# CH32V20xxx register map
Vendor: WCH Ltd.; File version: 1.0
Registers are 32-bit, read-write, reset 0x0 unless marked. A register's access mark holds for its fields unless they carry their own. Offsets are from the block's base; [hi:lo] are bit positions; {n}, {i} and the like mark numbered series.

## EXTI
Base 0x40010400
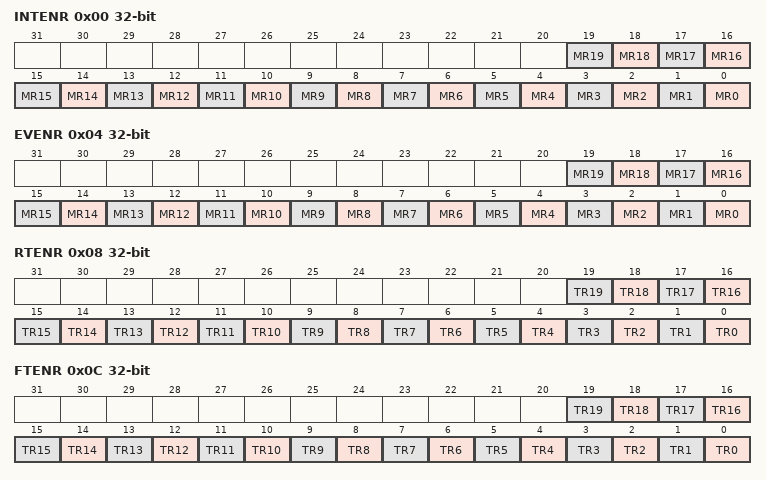
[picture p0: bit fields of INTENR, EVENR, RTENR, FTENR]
0x00 INTENR — Interrupt mask register (EXTI_INTENR)
  [n] MR{n} (n=0..19) — Interrupt Mask on line {n}
0x04 EVENR — Event mask register (EXTI_EVENR)
  [n] MR{n} (n=0..19) — Event Mask on line {n}
0x08 RTENR — Rising Trigger selection register (EXTI_RTENR)
  [n] TR{n} (n=0..19) — Rising trigger event configuration of line {n}
0x0C FTENR — Falling Trigger selection register (EXTI_FTENR)
  [n] TR{n} (n=0..19) — Falling trigger event configuration of line {n}
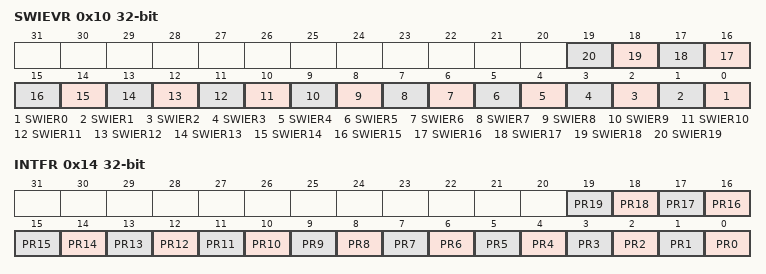
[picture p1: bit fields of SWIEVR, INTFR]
0x10 SWIEVR — Software interrupt event register (EXTI_SWIEVR)
  [n] SWIER{n} (n=0..19) — Software Interrupt on line {n}
0x14 INTFR — Pending register (EXTI_INTFR)
  [n] PR{n} (n=0..19) — Pending bit {n}

## RTC — Real time clock
Base 0x40002800
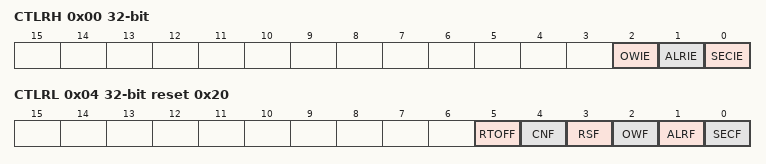
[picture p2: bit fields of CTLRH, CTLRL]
0x00 CTLRH — RTC Control Register High
  [2] OWIE — Overflow interrupt Enable
  [1] ALRIE — Alarm interrupt Enable
  [0] SECIE — Second interrupt Enable
0x04 CTLRL access per field reset 0x20 — RTC Control Register Low
  [5] RTOFF ro — RTC operation OFF
  [4] CNF rw — Configuration Flag
  [3] RSF rw — Registers Synchronized Flag
  [2] OWF rw — Overflow Flag
  [1] ALRF rw — Alarm Flag
  [0] SECF rw — Second Flag
0x08 PSCRH wo — RTC Prescaler Load Register High
  [3:0] PRLH
0x0C PSCRL wo reset 0x8000 — RTC Prescaler Load Register Low
  [15:0] PRLL — RTC Prescaler Divider Register Low
0x10 DIVH ro — RTC Prescaler Divider Register High
  [3:0] DIVH — RTC prescaler divider register high
0x14 DIVL ro reset 0x8000 — RTC Prescaler Divider Register Low
  [15:0] DIVL — RTC prescaler divider register Low
0x18 CNTH — RTC Counter Register High
  [15:0] CNTH — RTC counter register high
0x1C CNTL — RTC Counter Register Low
  [15:0] CNTL — RTC counter register Low
0x20 ALRMH wo reset 0xFFFF — RTC Alarm Register High
  [15:0] ALRH — RTC alarm register high
0x24 ALRML wo reset 0xFFFF — RTC Alarm Register Low
  [15:0] ALRL — RTC alarm register low

## BKP — Backup registers
Base 0x40006C00
{0x0+4i} DATAR{i} (i=1..10) — Backup data register (BKP_DR)
  [15:0] D{i} — Backup data
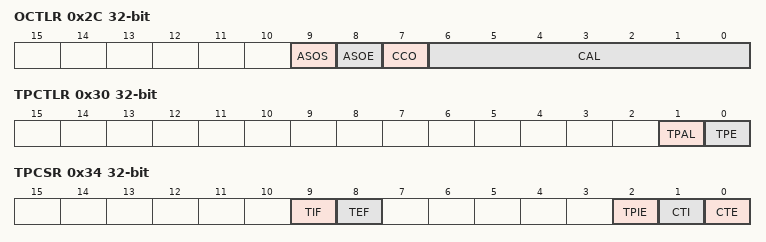
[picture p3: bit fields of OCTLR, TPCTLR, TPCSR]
0x2C OCTLR — RTC clock calibration register (BKP_OCTLR)
  [9] ASOS — Alarm or second output selection
  [8] ASOE — Alarm or second output enable
  [7] CCO — Calibration Clock Output
  [6:0] CAL — Calibration value
0x30 TPCTLR — Backup control register (BKP_TPCTLR)
  [1] TPAL — Tamper pin active level
  [0] TPE — Tamper pin enable
0x34 TPCSR access per field — BKP_TPCSR control/status register (BKP_CSR)
  [9] TIF ro — Tamper Interrupt Flag
  [8] TEF ro — Tamper Event Flag
  [2] TPIE rw — Tamper Pin interrupt enable
  [1] CTI wo — Clear Tamper Interrupt
  [0] CTE wo — Clear Tamper event
{0x14+4i} DATAR{i} (i=11..13) — Backup data register (BKP_DR)
  [15:0] DR{i} — Backup data
{0x14+4i} DATAR{i} (i=14..42) — Backup data register (BKP_DR)
  [15:0] D{i} — Backup data

## IWDG — Independent watchdog
Base 0x40003000
0x00 CTLR wo — Key register (IWDG_CTLR)
  [15:0] KEY — Key value
0x04 PSCR — Prescaler register (IWDG_PSCR)
  [2:0] PR — Prescaler divider
0x08 RLDR reset 0xFFF — Reload register (IWDG_RLDR)
  [11:0] RL — Watchdog counter reload value
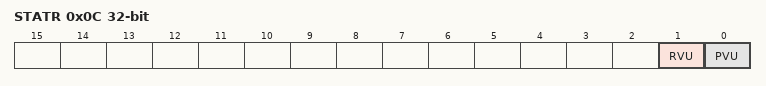
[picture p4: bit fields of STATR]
0x0C STATR ro — Status register (IWDG_SR)
  [1] RVU — Watchdog counter reload value update
  [0] PVU — Watchdog prescaler value update

## WWDG — Window watchdog
Base 0x40002C00
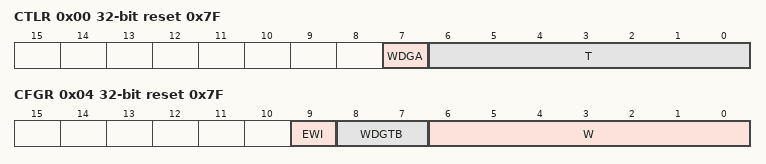
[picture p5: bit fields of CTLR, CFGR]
0x00 CTLR reset 0x7F — Control register (WWDG_CR)
  [7] WDGA — Activation bit
  [6:0] T — 7-bit counter (MSB to LSB)
0x04 CFGR reset 0x7F — Configuration register (WWDG_CFR)
  [9] EWI — Early Wakeup Interrupt
  [8:7] WDGTB — Timer Base
  [6:0] W — 7-bit window value
0x08 STATR — Status register (WWDG_SR)
  [0] WEIF — Early Wakeup Interrupt Flag

## I2C1 — Inter integrated circuit
Base 0x40005400
Same registers: I2C2 0x40005800
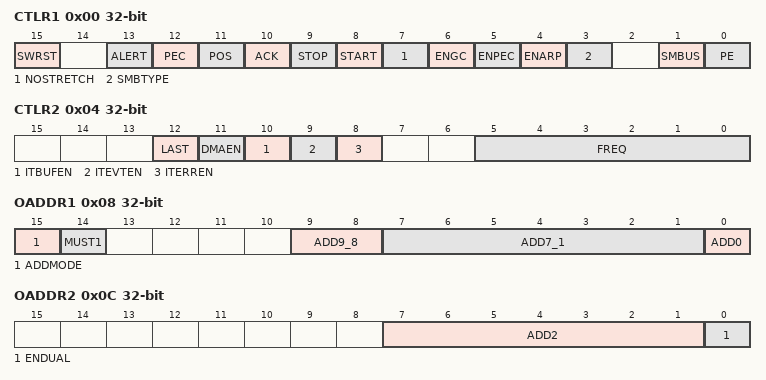
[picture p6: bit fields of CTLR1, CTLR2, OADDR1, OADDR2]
0x00 CTLR1 — Control register 1
  [15] SWRST — Software reset
  [13] ALERT — SMBus alert
  [12] PEC — Packet error checking
  [11] POS — Acknowledge/PEC Position (for data reception)
  [10] ACK — Acknowledge enable
  [9] STOP — Stop generation
  [8] START — Start generation
  [7] NOSTRETCH — Clock stretching disable (Slave mode)
  [6] ENGC — General call enable
  [5] ENPEC — PEC enable
  [4] ENARP — ARP enable
  [3] SMBTYPE — SMBus type
  [1] SMBUS — SMBus mode
  [0] PE — Peripheral enable
0x04 CTLR2 — Control register 2
  [12] LAST — DMA last transfer
  [11] DMAEN — DMA requests enable
  [10] ITBUFEN — Buffer interrupt enable
  [9] ITEVTEN — Event interrupt enable
  [8] ITERREN — Error interrupt enable
  [5:0] FREQ — Peripheral clock frequency
0x08 OADDR1 — Own address register 1
  [15] ADDMODE — Addressing mode (slave mode)
  [14] MUST1 — Must be 1
  [9:8] ADD9_8 — Interface address
  [7:1] ADD7_1 — Interface address
  [0] ADD0 — Interface address
0x0C OADDR2 — Own address register 2
  [7:1] ADD2 — Interface address
  [0] ENDUAL — Dual addressing mode enable
0x10 DATAR — Data register
  [7:0] DATAR — 8-bit data register
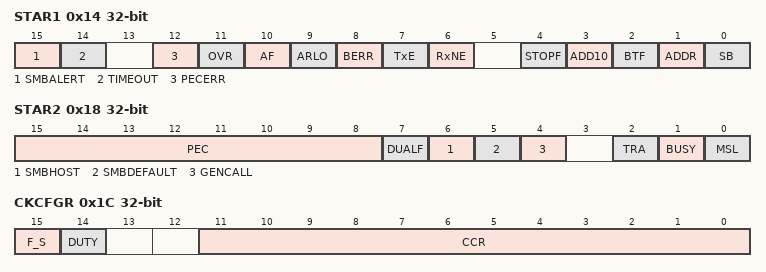
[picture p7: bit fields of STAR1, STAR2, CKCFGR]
0x14 STAR1 access per field — Status register 1
  [15] SMBALERT rw — SMBus alert
  [14] TIMEOUT rw — Timeout or Tlow error
  [12] PECERR rw — PEC Error in reception
  [11] OVR rw — Overrun/Underrun
  [10] AF rw — Acknowledge failure
  [9] ARLO rw — Arbitration lost (master mode)
  [8] BERR rw — Bus error
  [7] TxE ro — Data register empty (transmitters)
  [6] RxNE ro — Data register not empty (receivers)
  [4] STOPF ro — Stop detection (slave mode)
  [3] ADD10 ro — 10-bit header sent (Master mode)
  [2] BTF ro — Byte transfer finished
  [1] ADDR ro — Address sent (master mode)/matched (slave mode)
  [0] SB ro — Start bit (Master mode)
0x18 STAR2 ro — Status register 2
  [15:8] PEC — acket error checking register
  [7] DUALF — Dual flag (Slave mode)
  [6] SMBHOST — SMBus host header (Slave mode)
  [5] SMBDEFAULT — SMBus device default address (Slave mode)
  [4] GENCALL — General call address (Slave mode)
  [2] TRA — Transmitter/receiver
  [1] BUSY — Bus busy
  [0] MSL — Master/slave
0x1C CKCFGR — Clock control register
  [15] F_S — I2C master mode selection
  [14] DUTY — Fast mode duty cycle
  [11:0] CCR — Clock control register in Fast/Standard mode (Master mode)
0x20 RTR reset 0x2 — Raise time register
  [5:0] TRISE — Maximum rise time in Fast/Standard mode (Master mode)
